# STM32MP25_CM33 register map
File version: 1.3
CPU: CM33 r0p1, little endian, MPU, FPU, vendor SysTick, 8 interrupt priority bits
Registers are 32-bit, read-write, reset 0x0 unless marked. A register's access mark holds for its fields unless they carry their own. Offsets are from the block's base; [hi:lo] are bit positions; lines under a group give offsets from that group; {n}, {i} and the like mark numbered series; 'fields as' and 'values as' point back to an identical list.

## RCC (part 2 of 3) — RCC register block
Base 0x44200000
Same registers: RCC_S 0x54200000
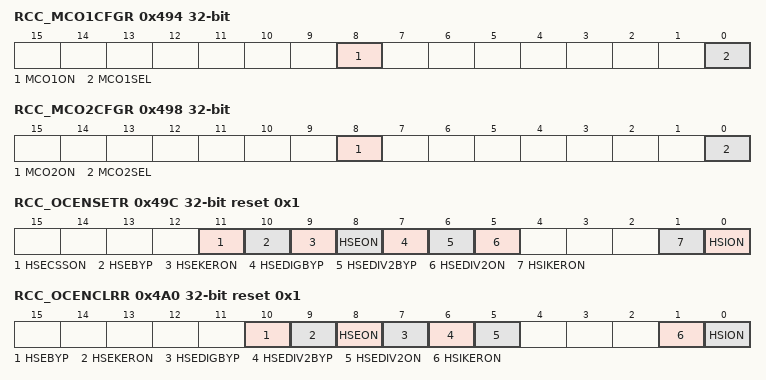
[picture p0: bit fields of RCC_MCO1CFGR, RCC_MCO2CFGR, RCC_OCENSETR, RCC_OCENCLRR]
0x494 RCC_MCO1CFGR — RCC MCO1 configuration register
  [8] MCO1ON — Control of MCO1 output
    0=MCO1 output disabled (default after reset); 1=MCO1 output enabled
  [0] MCO1SEL — MCO1 clock output selection
    0=Channel 61 output of the flexclkgen engine (default after reset); 1=Clock observation 0 of the flexclkgen engine
0x498 RCC_MCO2CFGR — RCC MCO2 configuration register
  [8] MCO2ON — Control of the MCO2 output
    0=MCO2 output disabled (default after reset); 1=MCO2 output enabled
  [0] MCO2SEL — MCO2 clock output selection
    0=Channel 62 output of the flexclkgen engine (default after reset); 1=Clock observation 1 of the flexclkgen engine
0x49C RCC_OCENSETR reset 0x1 — RCC oscillator clock enable set register
  [11] HSECSSON — HSECSSON bit set
    0=Reading 0 means that CSS on HSE is off (default after reset); 1=Writing 1 enables CSS on HSE
  [10] HSEBYP — HSEBYP bit set
    0=No effect; 1=Set the HSEBYP bit
  [9] HSEKERON — HSEKERON bit set
    0=No effect; 1=Set the HSEKERON bit
  [8] HSEON — HSEON bit set
    0=No effect; 1=Set HSEON bit
  [7] HSEDIGBYP — HSEDIGBYP bit set
    0=No effect; 1=Set HSEDIGBYP bit (digital bypass)
  [6] HSEDIV2BYP — HSEDIV2BYP bit set
    0=No effect; 1=Set HSEDIV2BYP bit
  [5] HSEDIV2ON — HSEDIV2ON bit set
    0=No effect; 1=Set HSEDIV2ON bit
  [1] HSIKERON — HSIKERON bit set
    0=No effect; 1=Set the HSIKERON bit
  [0] HSION — HSION bit set
    0=No effect; 1=Set the HSION bit
0x4A0 RCC_OCENCLRR reset 0x1 — RCC oscillator clock enable clear register
  [10] HSEBYP — HSEBYP bit clear
    0=No effect; 1=Clear the HSEBYP bit
  [9] HSEKERON — HSEKERON bit clear
    0=No effect; 1=Clear the HSEKERON bit
  [8] HSEON — HSEON bit clear
    0=No effect; 1=Clear the HSEON bit
  [7] HSEDIGBYP — HSEDIGBYP bit clear
    0=No effect; 1=Clear the HSEDIGBYP bit (analog bypass)
  [6] HSEDIV2BYP — HSEDIV2BYP bit clear
    0=No effect; 1=Clear the HSEDIV2BYP bit
  [5] HSEDIV2ON — HSEDIV2ON bit clear
    0=No effect; 1=Clear HSEDIV2ON bit
  [1] HSIKERON — HSIKERON bit clear
    0=No effect; 1=Clear the HSIKERON bit
  [0] HSION — HSION bit clear
    0=No effect; 1=Clear the HSION bit
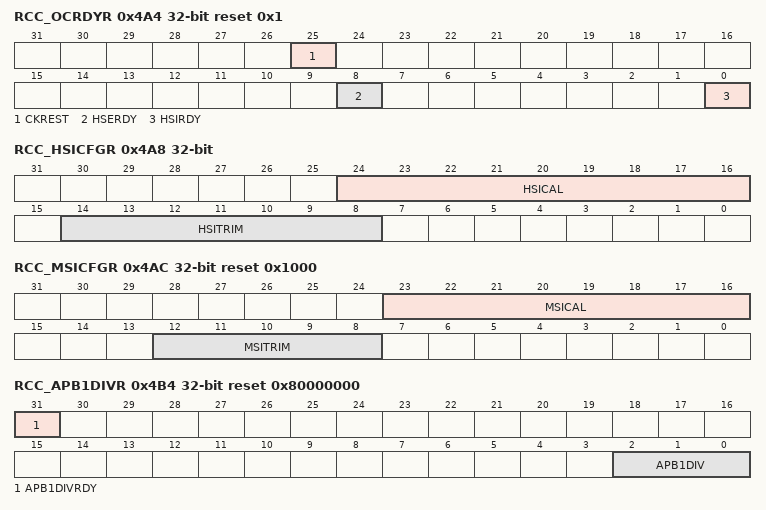
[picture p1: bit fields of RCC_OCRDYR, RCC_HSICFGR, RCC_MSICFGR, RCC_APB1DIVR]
0x4A4 RCC_OCRDYR ro reset 0x1 — RCC oscillator clock ready register
  [25] CKREST — Clock restore state machine status
    0=Clock restore process not ongoing (default after reset); 1=Clock restore process ongoing
  [8] HSERDY — HSE clock ready flag
    0=HSE clock not ready (default after reset); 1=HSE clock ready
  [0] HSIRDY — HSI clock ready flag
    0=HSI clock not ready (default after reset); 1=HSI clock ready
0x4A8 RCC_HSICFGR — RCC HSI configuration register
  [24:16] HSICAL ro — HSI clock calibration
  [14:8] HSITRIM — HSI clock trimming
    64=bsec_hsi_cal[8:0] - 64; 65=bsec_hsi_cal[8:0] - 63; 0=bsec_hsi_cal[8:0] (default after reset); 62=bsec_hsi_cal[8:0] + 62; 63=bsec_hsi_cal[8:0] + 63
0x4AC RCC_MSICFGR reset 0x1000 — RCC MSI configuration register
  [23:16] MSICAL ro — MSI clock calibration
  [12:8] MSITRIM — MSI clock trimming
0x4B0 RCC_RTCDIVR — RCC RTC clock divider register
  [5:0] RTCDIV — HSE division factor for RTC clock
    0=HSE (default after reset); 1=HSE/2; 2=HSE/3; 3=HSE/4; 62=HSE/63; 63=HSE/64
0x4B4 RCC_APB1DIVR reset 0x80000000 — RCC APB1 clock divider register
  [31] APB1DIVRDY ro — APB1 clock prescaler status
    0=The new division factor is not yet taken into account; 1=The new division factor is taken into account (default after reset)
  [2:0] APB1DIV — APB1 clock divider
    0=ck_icn_ls_mcu (default after reset); 1=ck_icn_ls_mcu / 2; 2=ck_icn_ls_mcu / 4; 3=ck_icn_ls_mcu / 8; 4=ck_icn_ls_mcu / 16
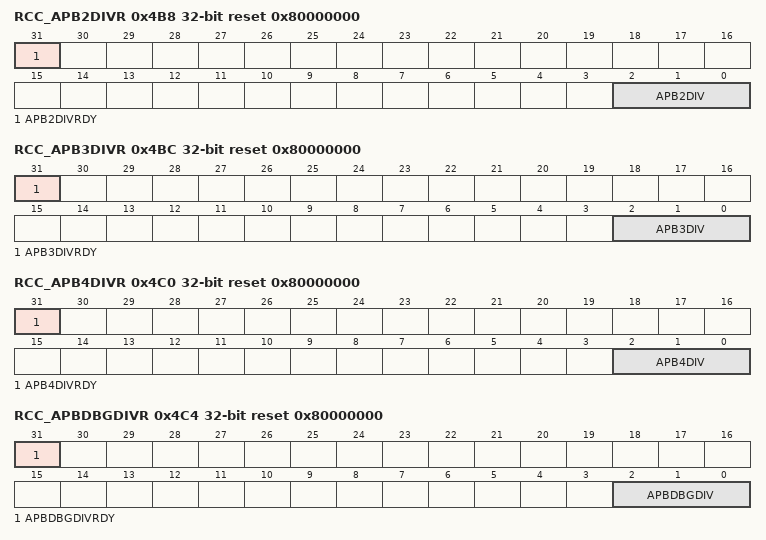
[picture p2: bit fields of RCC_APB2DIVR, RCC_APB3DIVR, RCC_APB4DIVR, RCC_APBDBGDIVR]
0x4B8 RCC_APB2DIVR reset 0x80000000 — RCC APB2 clock divider register
  [31] APB2DIVRDY ro — APB2 clock prescaler status
    values as RCC_APB1DIVR.APB1DIVRDY
  [2:0] APB2DIV — APB2 clock divider
    values as RCC_APB1DIVR.APB1DIV
0x4BC RCC_APB3DIVR reset 0x80000000 — RCC APB3 clock divider register
  [31] APB3DIVRDY ro — APB3 clock prescaler status
    0=The new division factor is not yet taken into account; 1=The new division factor is taken into account
  [2:0] APB3DIV — APB3 clock divider
    values as RCC_APB1DIVR.APB1DIV
0x4C0 RCC_APB4DIVR reset 0x80000000 — RCC APB4 clock divider register
  [31] APB4DIVRDY ro — APB4 clock divider status
    values as RCC_APB1DIVR.APB1DIVRDY
  [2:0] APB4DIV — APB4 clock divider
    values as RCC_APB1DIVR.APB1DIV
0x4C4 RCC_APBDBGDIVR reset 0x80000000 — RCC APBDBG clock divider register
  [31] APBDBGDIVRDY ro — APBDBG clock divider status
    values as RCC_APB1DIVR.APB1DIVRDY
  [2:0] APBDBGDIV — APBDBG clock divider
    values as RCC_APB1DIVR.APB1DIV
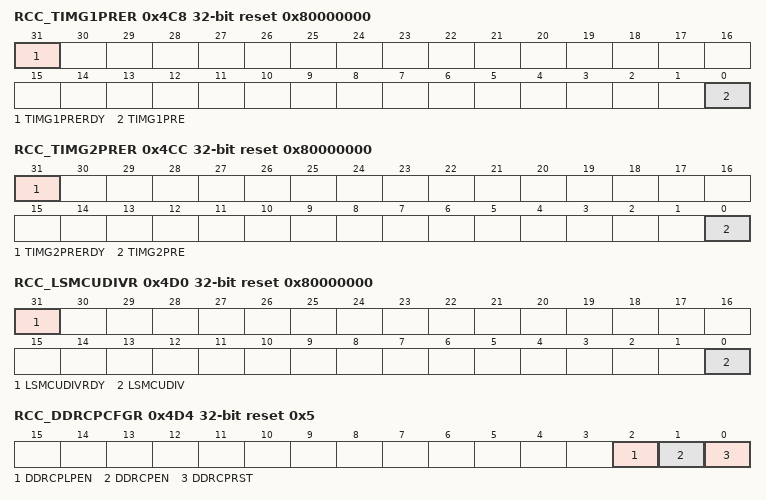
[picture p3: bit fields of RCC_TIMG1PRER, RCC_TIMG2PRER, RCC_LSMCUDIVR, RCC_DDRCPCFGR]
0x4C8 RCC_TIMG1PRER reset 0x80000000 — RCC TIM group 1 prescaler register
  [31] TIMG1PRERDY ro — Clock prescaler status for timers of group 1
    values as RCC_APB1DIVR.APB1DIVRDY
  [0] TIMG1PRE — Clock prescaler selection for timers of group 1
    0=Timer kernel clock is equal to ck_icn_ls_mcu if APB1DIV corresponds to a division; 1=Timer kernel clock is equal to ck_icn_ls_mcu if APB1DIV corresponds to a division
0x4CC RCC_TIMG2PRER reset 0x80000000 — RCC TIM group 2 prescaler register
  [31] TIMG2PRERDY ro — Clock prescaler status for timers of group 2
    values as RCC_APB3DIVR.APB3DIVRDY
  [0] TIMG2PRE — Clock prescaler selection for timers of group 2
    0=Timer kernel clock is equal to ck_icn_ls_mcu if APB2DIV corresponds to a division; 1=Timer kernel clock is equal to ck_icn_ls_mcu if APB2DIV corresponds to division
0x4D0 RCC_LSMCUDIVR reset 0x80000000 — RCC LSMCU clock divider register
  [31] LSMCUDIVRDY ro — LSMCU clock divider status
    values as RCC_APB1DIVR.APB1DIVRDY
  [0] LSMCUDIV — LSMCU clock divider
    0=ck_icn_hs_mcu (default after reset); 1=ck_icn_hs_mcu / 2
0x4D4 RCC_DDRCPCFGR reset 0x5 — RCC DDRC AXI port configuration register
  [2] DDRCPLPEN — DDRC AXI port clock enable during CSleep
    0=Writing 0 disables peripheral clocks in CSleep; 1=Writing 1 enables peripheral clocks in CSleep
  [1] DDRCPEN — DDRC AXI port clock enable
    0=Writing 0 disables peripheral clocks; 1=Writing 1 enables peripheral clocks
  [0] DDRCPRST — DDRC AXI port reset
    0=Writing 0 releases DDRC AXI port interface reset; 1=Writing 1 sets DDRC AXI port interface under reset
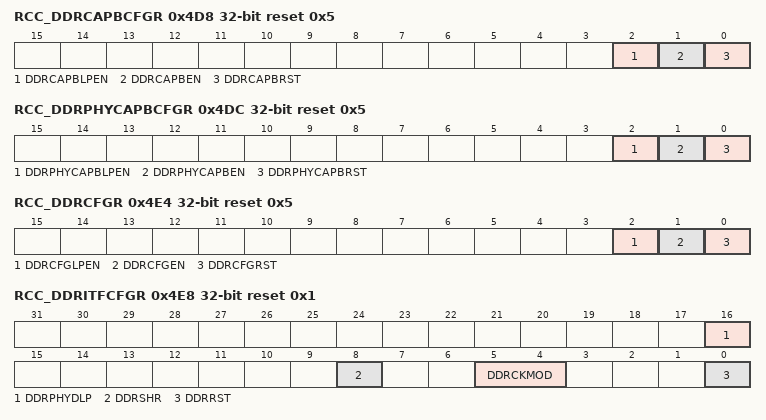
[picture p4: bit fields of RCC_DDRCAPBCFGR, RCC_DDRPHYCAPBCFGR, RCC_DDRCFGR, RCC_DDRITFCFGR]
0x4D8 RCC_DDRCAPBCFGR reset 0x5 — RCC DDRC APB configuration register
  [2] DDRCAPBLPEN — DDRC APB clock enable during CSleep
    values as RCC_DDRCPCFGR.DDRCPLPEN
  [1] DDRCAPBEN — DDRC APB clock enable
    values as RCC_DDRCPCFGR.DDRCPEN
  [0] DDRCAPBRST — DDRC APB reset
    0=Writing 0 releases DDRC APB interface reset; 1=Writing 1 sets DDRC APB interface under reset
0x4DC RCC_DDRPHYCAPBCFGR reset 0x5 — RCC DDRPHYC APB configuration register
  [2] DDRPHYCAPBLPEN — DDRPHYC APB clock enable during CSleep
    values as RCC_DDRCPCFGR.DDRCPLPEN
  [1] DDRPHYCAPBEN — DDRPHYC APB clock enable
    values as RCC_DDRCPCFGR.DDRCPEN
  [0] DDRPHYCAPBRST — DDRPHYC APB reset
    0=Writing 0 releases DDRPHYC APB interface reset; 1=Writing 1 sets DDRPHYC APB interface under reset
0x4E0 RCC_DDRPHYCCFGR — RCC DDRPHYC configuration register
  [1] DDRPHYCEN — DDRPHYC kernel clock enable
    0=Writing 0 disables DDRPHYC kernel clock; 1=Writing 1 enables DDRPHYC kernel clock
0x4E4 RCC_DDRCFGR reset 0x5 — RCC DDR configuration register
  [2] DDRCFGLPEN — DDR APB configuration clock enable during CSleep
    values as RCC_DDRCPCFGR.DDRCPLPEN
  [1] DDRCFGEN — DDR APB configuration clock enable
    values as RCC_DDRCPCFGR.DDRCPEN
  [0] DDRCFGRST — DDR APB configuration reset
    0=Writing 0 releases DDR APB configuration interface reset; 1=Writing 1 sets DDR APB configuration interface under reset
0x4E8 RCC_DDRITFCFGR reset 0x1 — RCC DDR interface configuration register
  [16] DDRPHYDLP — DDRPHY deep low-power mode (LP2 or LP3)
    0=DDRPHY not set in low-power mode (default after reset); 1=DDRPHY set in deep low-power mode
  [8] DDRSHR — DDR peripheral mode
    0=DDR defined as single peripheral (default after reset); 1=DDR defined as shared peripheral
  [5:4] DDRCKMOD — RCC mode for DDR clock control
    0=Normal mode: dphy_ker_ck and dphy_ker_byp_ck gating depends on DDRPHYCEN, DDRSHR, DDRPHYDLP, and CPU1 or system mode; 1=ASR (automatic self-refresh) mode: ddrc_ker_ck is gated automatically according to cactive_ddrc signal; 2=HSR (hardware self-refresh) mode: ddrc_ker_ck gating depends on DDRCPEN, DDRCLPEN, DDRSHR, and CPU1 or system mode
  [0] DDRRST — DDR core and PHY reset
    0=DDR core and PHY are not reset; 1=DDR core and PHY are reset (default after reset)
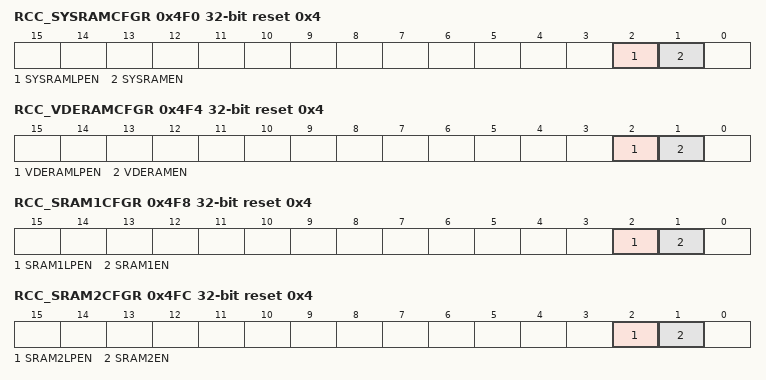
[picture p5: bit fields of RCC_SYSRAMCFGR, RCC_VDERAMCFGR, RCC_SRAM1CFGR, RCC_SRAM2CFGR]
0x4F0 RCC_SYSRAMCFGR reset 0x4 — RCC SYSRAM configuration register
  [2] SYSRAMLPEN — SYSRAM clock enable during CSleep
    values as RCC_DDRCPCFGR.DDRCPLPEN
  [1] SYSRAMEN — SYSRAM clock enable
    values as RCC_DDRCPCFGR.DDRCPEN
0x4F4 RCC_VDERAMCFGR reset 0x4 — RCC VDERAM configuration register
  [2] VDERAMLPEN — VDERAM clock enable during CSleep
    values as RCC_DDRCPCFGR.DDRCPLPEN
  [1] VDERAMEN — VDERAM clock enable
    values as RCC_DDRCPCFGR.DDRCPEN
0x4F8 RCC_SRAM1CFGR reset 0x4 — RCC SRAM1 configuration register
  [2] SRAM1LPEN — SRAM1 clock enable during CSleep
    values as RCC_DDRCPCFGR.DDRCPLPEN
  [1] SRAM1EN — SRAM1 clock enable
    values as RCC_DDRCPCFGR.DDRCPEN
0x4FC RCC_SRAM2CFGR reset 0x4 — RCC SRAM2 configuration register
  [2] SRAM2LPEN — SRAM2 clock enable during CSleep
    values as RCC_DDRCPCFGR.DDRCPLPEN
  [1] SRAM2EN — SRAM2 clock enable
    values as RCC_DDRCPCFGR.DDRCPEN
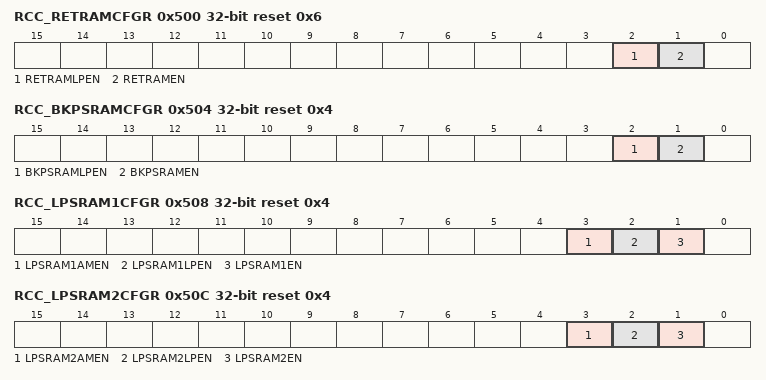
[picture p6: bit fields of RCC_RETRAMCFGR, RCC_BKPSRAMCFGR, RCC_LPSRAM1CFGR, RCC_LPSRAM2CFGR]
0x500 RCC_RETRAMCFGR reset 0x6 — RCC RETRAM configuration register
  [2] RETRAMLPEN — RETRAM clock enable during CSleep
    values as RCC_DDRCPCFGR.DDRCPLPEN
  [1] RETRAMEN — RETRAM clock enable
    values as RCC_DDRCPCFGR.DDRCPEN
0x504 RCC_BKPSRAMCFGR reset 0x4 — RCC BKPSRAM configuration register
  [2] BKPSRAMLPEN — BKPSRAM clock enable during CSleep
    values as RCC_DDRCPCFGR.DDRCPLPEN
  [1] BKPSRAMEN — BKPSRAM clock enable
    values as RCC_DDRCPCFGR.DDRCPEN
0x508 RCC_LPSRAM1CFGR reset 0x4 — RCC LPSRAM1 configuration register
  [3] LPSRAM1AMEN — LPSRAM1 autonomous clock mode enable
    0=Writing 0 disables autonomous clock mode; 1=Writing 1 enables autonomous clock mode
  [2] LPSRAM1LPEN — LPSRAM1 clock enable during CSleep
    values as RCC_DDRCPCFGR.DDRCPLPEN
  [1] LPSRAM1EN — LPSRAM1 clock enable
    values as RCC_DDRCPCFGR.DDRCPEN
0x50C RCC_LPSRAM2CFGR reset 0x4 — RCC LPSRAM2 configuration register
  [3] LPSRAM2AMEN — LPSRAM2 autonomous clock mode enable
    0=Writing 0 disables autonomous clock mode; 1=Writing 1 enables the autonomous clock mode
  [2] LPSRAM2LPEN — LPSRAM2 clock enable during CSleep
    values as RCC_DDRCPCFGR.DDRCPLPEN
  [1] LPSRAM2EN — LPSRAM2 clock enable
    values as RCC_DDRCPCFGR.DDRCPEN
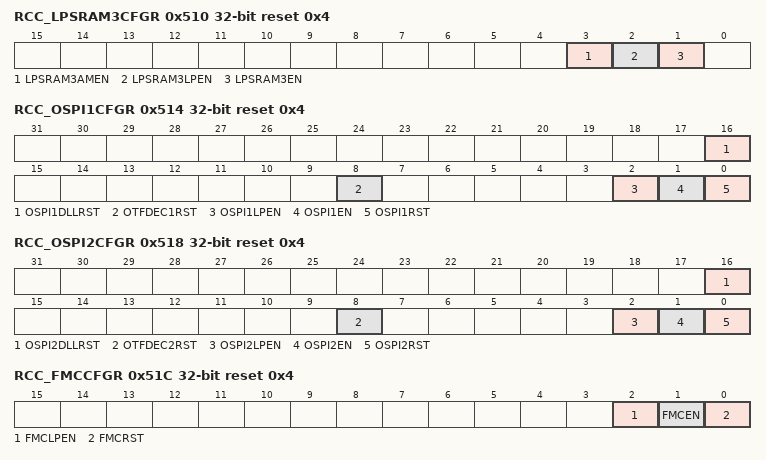
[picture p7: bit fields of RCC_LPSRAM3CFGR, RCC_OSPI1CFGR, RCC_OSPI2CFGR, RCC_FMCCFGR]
0x510 RCC_LPSRAM3CFGR reset 0x4 — RCC LPSRAM3 configuration register
  [3] LPSRAM3AMEN — LPSRAM3 autonomous clock mode enable
    values as RCC_LPSRAM2CFGR.LPSRAM2AMEN
  [2] LPSRAM3LPEN — LPSRAM3 clock enable during CSleep
    values as RCC_DDRCPCFGR.DDRCPLPEN
  [1] LPSRAM3EN — LPSRAM3 clock enable
    values as RCC_DDRCPCFGR.DDRCPEN
0x514 RCC_OSPI1CFGR reset 0x4 — RCC OCTOSPI1 configuration register
  [16] OSPI1DLLRST — OCTOSPI1 DLL reset
    0=Writing 0 releases OCTOSPI1 DLL reset; 1=Writing 1 asserts OCTOSPI1 DLL reset
  [8] OTFDEC1RST — OTFDEC1 reset
    0=Writing 0 releases OTFDEC1 reset; 1=Writing 1 asserts OTFDEC1 reset
  [2] OSPI1LPEN — OCTOSPI1, OTFDEC1 and OCTOSPI1 delay (DLYBOSPI1) clock enable duringCSleep
    values as RCC_DDRCPCFGR.DDRCPLPEN
  [1] OSPI1EN — OCTOSPI1 and OTFDEC1 clock enable
    values as RCC_DDRCPCFGR.DDRCPEN
  [0] OSPI1RST — OCTOSPI1 reset
    0=Writing 0 releases OCTOSPI1 reset; 1=Writing 1 asserts OCTOSPI1 reset
0x518 RCC_OSPI2CFGR reset 0x4 — RCC OCTOSPI2 configuration register
  [16] OSPI2DLLRST — OCTOSPI2 DLL reset
    0=Writing 0 releases OCTOSPI2 DLL reset; 1=Writing 1 asserts OCTOSPI2 DLL reset
  [8] OTFDEC2RST — OTFDEC2 reset
    0=Writing 0 releases OTFDEC2 reset; 1=Writing 1 asserts OTFDEC2 reset
  [2] OSPI2LPEN — OCTOSPI2 and OTFDEC2 clock enable during CSleep
    values as RCC_DDRCPCFGR.DDRCPLPEN
  [1] OSPI2EN — OCTOSPI2 and OTFDEC2 clock enable
    values as RCC_DDRCPCFGR.DDRCPEN
  [0] OSPI2RST — OCTOSPI2 reset
    0=Writing 0 releases OCTOSPI2 reset; 1=Writing 1 asserts OCTOSPI2 reset
0x51C RCC_FMCCFGR reset 0x4 — RCC FMC configuration register
  [2] FMCLPEN — FMC clock enable during CSleep
    values as RCC_DDRCPCFGR.DDRCPLPEN
  [1] FMCEN — FMC clock enable
    values as RCC_DDRCPCFGR.DDRCPEN
  [0] FMCRST — FMC reset
    0=Writing 0 releases FMC reset; 1=Writing 1 asserts FMC reset
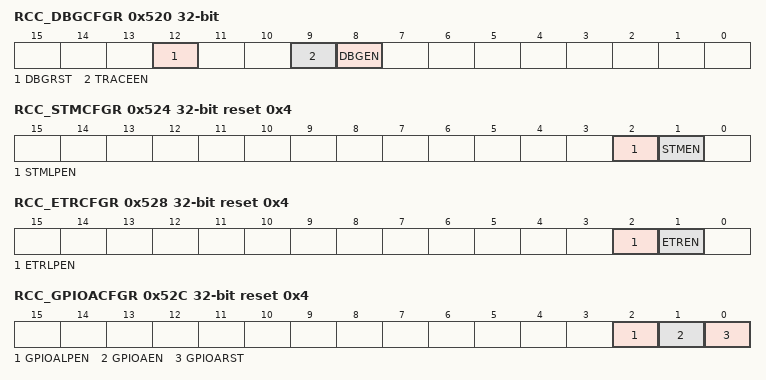
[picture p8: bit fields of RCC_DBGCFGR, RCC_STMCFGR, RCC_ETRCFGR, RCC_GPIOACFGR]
0x520 RCC_DBGCFGR — RCC debug configuration register
  [12] DBGRST — Debug function reset
    0=Trace and debug parts are not reset (default after reset); 1=Trace and debug parts are under reset
  [9] TRACEEN — Clock enable for trace port interface
    0=Clock for trace function disabled (default after reset); 1=Clock for trace function enabled
  [8] DBGEN — Debug function clock enable
    0=Enabling of clocks for debug function is controlled by cdbgpwrupreq signal from DAP (default after reset); 1=Clocks for debug function are enabled
0x524 RCC_STMCFGR reset 0x4 — RCC STM configuration register
  [2] STMLPEN — STM clock enable during CSleep
    values as RCC_DDRCPCFGR.DDRCPLPEN
  [1] STMEN — STM clock enable
    values as RCC_DDRCPCFGR.DDRCPEN
0x528 RCC_ETRCFGR reset 0x4 — RCC ETR configuration register
  [2] ETRLPEN — ETR clock enable during CSleep
    values as RCC_DDRCPCFGR.DDRCPLPEN
  [1] ETREN — ETR clocks enable
    values as RCC_DDRCPCFGR.DDRCPEN
0x52C RCC_GPIOACFGR reset 0x4 — RCC GPIOA configuration register
  [2] GPIOALPEN — GPIO x clock enable during CSleep
    values as RCC_DDRCPCFGR.DDRCPLPEN
  [1] GPIOAEN — GPIO x clock enable
    values as RCC_DDRCPCFGR.DDRCPEN
  [0] GPIOARST — GPIO x reset
    0=Writing 0 releases GPIOx reset; 1=Writing 1 asserts GPIOx reset
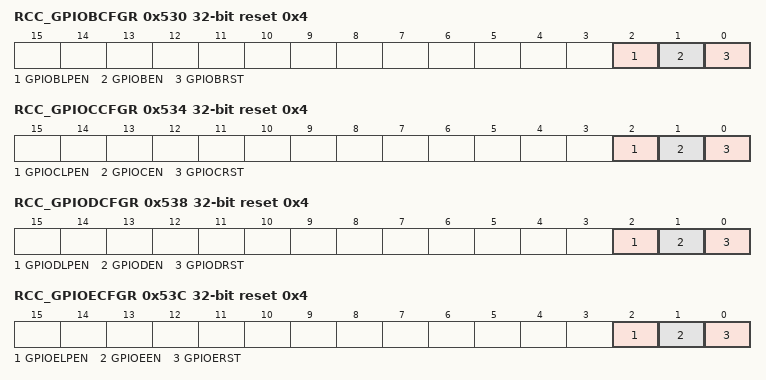
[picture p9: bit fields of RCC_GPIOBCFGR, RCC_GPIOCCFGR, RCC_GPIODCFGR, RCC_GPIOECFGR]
0x530 RCC_GPIOBCFGR reset 0x4 — RCC GPIOB configuration register
  [2] GPIOBLPEN — GPIO x clock enable during CSleep
    values as RCC_DDRCPCFGR.DDRCPLPEN
  [1] GPIOBEN — GPIO x clock enable
    values as RCC_DDRCPCFGR.DDRCPEN
  [0] GPIOBRST — GPIO x reset
    values as RCC_GPIOACFGR.GPIOARST
0x534 RCC_GPIOCCFGR reset 0x4 — RCC GPIOC configuration register
  [2] GPIOCLPEN — GPIO x clock enable during CSleep
    values as RCC_DDRCPCFGR.DDRCPLPEN
  [1] GPIOCEN — GPIO x clock enable
    values as RCC_DDRCPCFGR.DDRCPEN
  [0] GPIOCRST — GPIO x reset
    values as RCC_GPIOACFGR.GPIOARST
0x538 RCC_GPIODCFGR reset 0x4 — RCC GPIOD configuration register
  [2] GPIODLPEN — GPIO x clock enable during CSleep
    values as RCC_DDRCPCFGR.DDRCPLPEN
  [1] GPIODEN — GPIO x clock enable
    values as RCC_DDRCPCFGR.DDRCPEN
  [0] GPIODRST — GPIO x reset
    values as RCC_GPIOACFGR.GPIOARST
0x53C RCC_GPIOECFGR reset 0x4 — RCC GPIOE configuration register
  [2] GPIOELPEN — GPIO x clock enable during CSleep
    values as RCC_DDRCPCFGR.DDRCPLPEN
  [1] GPIOEEN — GPIO x clock enable
    values as RCC_DDRCPCFGR.DDRCPEN
  [0] GPIOERST — GPIO x reset
    values as RCC_GPIOACFGR.GPIOARST
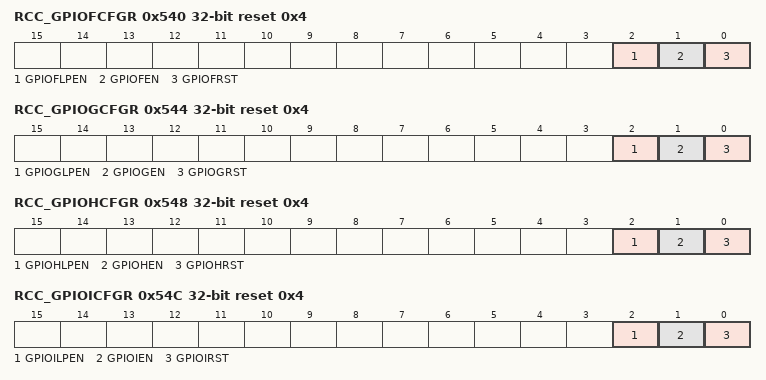
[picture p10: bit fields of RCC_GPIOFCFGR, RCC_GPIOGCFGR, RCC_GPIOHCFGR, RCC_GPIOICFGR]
0x540 RCC_GPIOFCFGR reset 0x4 — RCC GPIOF configuration register
  [2] GPIOFLPEN — GPIO x clock enable during CSleep
    values as RCC_DDRCPCFGR.DDRCPLPEN
  [1] GPIOFEN — GPIO x clock enable
    values as RCC_DDRCPCFGR.DDRCPEN
  [0] GPIOFRST — GPIO x reset
    values as RCC_GPIOACFGR.GPIOARST
0x544 RCC_GPIOGCFGR reset 0x4 — RCC GPIOG configuration register
  [2] GPIOGLPEN — GPIO x clock enable during CSleep
    values as RCC_DDRCPCFGR.DDRCPLPEN
  [1] GPIOGEN — GPIO x clock enable
    values as RCC_DDRCPCFGR.DDRCPEN
  [0] GPIOGRST — GPIO x reset
    values as RCC_GPIOACFGR.GPIOARST
0x548 RCC_GPIOHCFGR reset 0x4 — RCC GPIOH configuration register
  [2] GPIOHLPEN — GPIO x clock enable during CSleep
    values as RCC_DDRCPCFGR.DDRCPLPEN
  [1] GPIOHEN — GPIO x clock enable
    values as RCC_DDRCPCFGR.DDRCPEN
  [0] GPIOHRST — GPIO x reset
    values as RCC_GPIOACFGR.GPIOARST
0x54C RCC_GPIOICFGR reset 0x4 — RCC GPIOI configuration register
  [2] GPIOILPEN — GPIO x clock enable during CSleep
    values as RCC_DDRCPCFGR.DDRCPLPEN
  [1] GPIOIEN — GPIO x clock enable
    values as RCC_DDRCPCFGR.DDRCPEN
  [0] GPIOIRST — GPIO x reset
    values as RCC_GPIOACFGR.GPIOARST
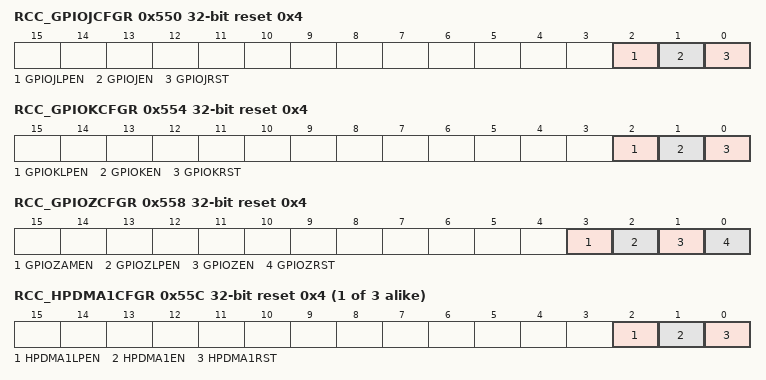
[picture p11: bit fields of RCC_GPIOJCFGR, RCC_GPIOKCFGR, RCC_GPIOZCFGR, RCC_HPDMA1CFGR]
0x550 RCC_GPIOJCFGR reset 0x4 — RCC GPIOJ configuration register
  [2] GPIOJLPEN — GPIO x clock enable during CSleep
    values as RCC_DDRCPCFGR.DDRCPLPEN
  [1] GPIOJEN — GPIO x clock enable
    values as RCC_DDRCPCFGR.DDRCPEN
  [0] GPIOJRST — GPIO x reset
    values as RCC_GPIOACFGR.GPIOARST
0x554 RCC_GPIOKCFGR reset 0x4 — RCC GPIOK configuration register
  [2] GPIOKLPEN — GPIO x clock enable during CSleep
    values as RCC_DDRCPCFGR.DDRCPLPEN
  [1] GPIOKEN — GPIO x clock enable
    values as RCC_DDRCPCFGR.DDRCPEN
  [0] GPIOKRST — GPIO x reset
    values as RCC_GPIOACFGR.GPIOARST
0x558 RCC_GPIOZCFGR reset 0x4 — RCC GPIOZ configuration register
  [3] GPIOZAMEN — GPIOZ autonomous clock mode enable
    0=Writing 0 disables the autonomous clock mode; 1=Writing 1 enables the autonomous clock mode
  [2] GPIOZLPEN — GPIOZ clock enable during CSleep
    values as RCC_DDRCPCFGR.DDRCPLPEN
  [1] GPIOZEN — GPIOZ clock enable
    values as RCC_DDRCPCFGR.DDRCPEN
  [0] GPIOZRST — GPIOZ reset
    0=Writing 0 releases GPIOZ reset; 1=Writing 1 asserts GPIOZ reset
{0x558+4i} RCC_HPDMA{i}CFGR reset 0x4 (i=1..3) — RCC HPDMA{i} configuration register
  [2] HPDMA{i}LPEN — HPDMA{i} clock enable during CSleep
    values as RCC_DDRCPCFGR.DDRCPLPEN
  [1] HPDMA{i}EN — HPDMA{i} clock enable
    values as RCC_DDRCPCFGR.DDRCPEN
  [0] HPDMA{i}RST — HPDMA{i} reset
    0=Writing 0 releases HPDMA{i} reset; 1=Writing 1 asserts HPDMA{i} reset
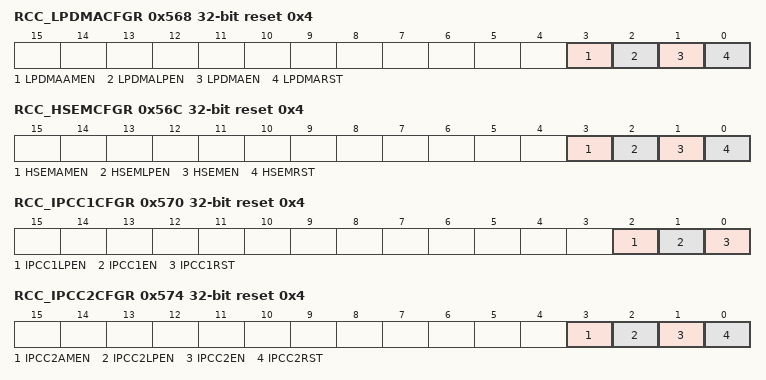
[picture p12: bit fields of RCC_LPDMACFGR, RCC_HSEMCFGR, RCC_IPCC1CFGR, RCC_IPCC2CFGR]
0x568 RCC_LPDMACFGR reset 0x4 — RCC LPDMA1 configuration register
  [3] LPDMAAMEN — LPDMA1 autonomous clock mode enable
    values as RCC_LPSRAM1CFGR.LPSRAM1AMEN
  [2] LPDMALPEN — LPDMA1 clock enable during CSleep
    values as RCC_DDRCPCFGR.DDRCPLPEN
  [1] LPDMAEN — LPDMA1 clock enable
    values as RCC_DDRCPCFGR.DDRCPEN
  [0] LPDMARST — LPDMA1 reset
    0=Writing 0 releases LPDMA1 reset; 1=Writing 1 asserts LPDMA1 reset
0x56C RCC_HSEMCFGR reset 0x4 — RCC HSEM configuration register
  [3] HSEMAMEN — HSEM autonomous clock mode enable
    values as RCC_LPSRAM1CFGR.LPSRAM1AMEN
  [2] HSEMLPEN — HSEM clock enable during CSleep
    values as RCC_DDRCPCFGR.DDRCPLPEN
  [1] HSEMEN — HSEM clock enable
    values as RCC_DDRCPCFGR.DDRCPEN
  [0] HSEMRST — HSEM reset
    0=Writing 0 releases HSEM reset; 1=Writing 1 asserts HSEM reset
0x570 RCC_IPCC1CFGR reset 0x4 — RCC IPCC1 configuration register
  [2] IPCC1LPEN — IPCC1 clock enable during CSleep
    values as RCC_DDRCPCFGR.DDRCPLPEN
  [1] IPCC1EN — IPCC1 clock enable
    values as RCC_DDRCPCFGR.DDRCPEN
  [0] IPCC1RST — IPCC1 reset
    0=Writing 0 releases IPCC1 reset; 1=Writing 1 asserts IPCC1 reset
0x574 RCC_IPCC2CFGR reset 0x4 — RCC IPCC2 configuration register
  [3] IPCC2AMEN — IPCC2 autonomous clock mode enable
    values as RCC_LPSRAM1CFGR.LPSRAM1AMEN
  [2] IPCC2LPEN — IPCC2 clock enable during CSleep
    values as RCC_DDRCPCFGR.DDRCPLPEN
  [1] IPCC2EN — IPCC2 clock enable
    values as RCC_DDRCPCFGR.DDRCPEN
  [0] IPCC2RST — IPCC2 reset
    0=Writing 0 releases IPCC2 reset; 1=Writing 1 asserts IPCC2 reset
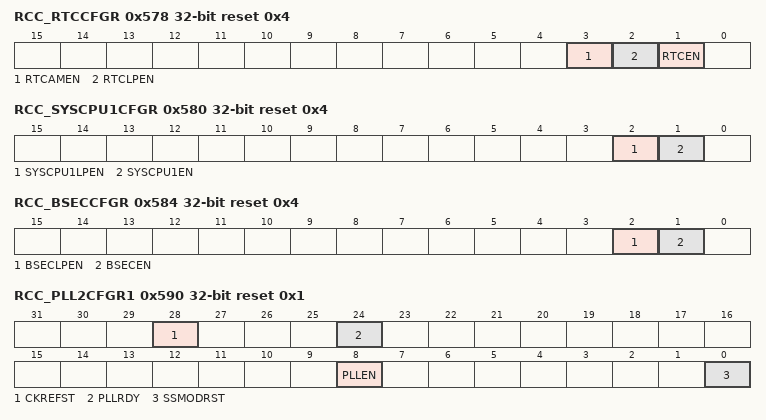
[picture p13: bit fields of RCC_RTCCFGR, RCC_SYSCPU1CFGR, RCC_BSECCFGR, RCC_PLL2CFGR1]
0x578 RCC_RTCCFGR reset 0x4 — RCC RTC configuration register
  [3] RTCAMEN — RTC autonomous clock mode enable
    values as RCC_LPSRAM1CFGR.LPSRAM1AMEN
  [2] RTCLPEN — RTC bus clock enable during CSleep
    0=Writing 0 disables APB clock in CSleep; 1=Writing 1 enables APB clock in CSleep
  [1] RTCEN — RTC bus clock enable
    0=Writing 0 disables APB clock; 1=Writing 1 enables APB clock
0x580 RCC_SYSCPU1CFGR reset 0x4 — RCC SYSCPU1 configuration register
  [2] SYSCPU1LPEN — CPU1 system configuration clock enable during CSleep
    values as RCC_RTCCFGR.RTCLPEN
  [1] SYSCPU1EN — CPU1 system configuration clock enable
    values as RCC_RTCCFGR.RTCEN
0x584 RCC_BSECCFGR reset 0x4 — RCC BSEC configuration register
  [2] BSECLPEN — BSEC clock enable during CSleep
    values as RCC_RTCCFGR.RTCLPEN
  [1] BSECEN — BSEC clock enable
    values as RCC_RTCCFGR.RTCEN
0x590 RCC_PLL2CFGR1 reset 0x1 — RCC PLL2 configuration register 1
  [28] CKREFST — PLLx reference clock state
    0=Reading 0 means that PLLx reference clock is not running; 1=Reading 1 means that PLLx reference clock is running
  [24] PLLRDY ro — PLLx clock ready flag
    0=PLLx unlocked (default after reset); 1=PLLx locked
  [8] PLLEN — PLLx enable
    0=PLLx off (default after reset); 1=PLLx on
  [0] SSMODRST — PLLx spread-spectrum modulator reset
    0=PLLx spread-spectrum modulator reset module is released; 1=PLLx spread-spectrum modulator reset module is asserted (default after reset)
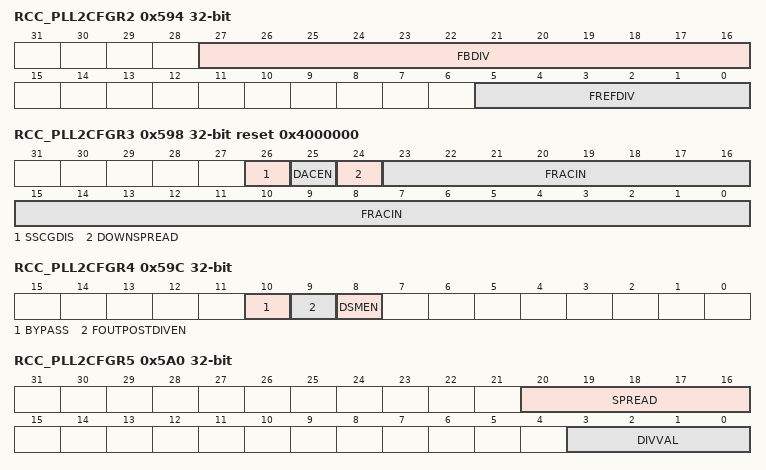
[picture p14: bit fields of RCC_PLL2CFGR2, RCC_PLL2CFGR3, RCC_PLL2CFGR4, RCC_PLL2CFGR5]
0x594 RCC_PLL2CFGR2 — RCC PLL2 configuration register 2
  [27:16] FBDIV — PLLx VCO multiplication factor
  [5:0] FREFDIV — PLLx reference input clock divide frequency ratio
    0=Not applicable when PLLx is enabled; 1=FREF divided by 1 (min value); 2=FREF divided by 2; 3=FREF divided by 3; {v}=FREF divided by {v} (v=60..63)
0x598 RCC_PLL2CFGR3 reset 0x4000000 — RCC PLL2 configuration register 3
  [26] SSCGDIS — PLLx spread-spectrum modulator enable
    0=PLLx spread-spectrum modulator enabled; 1=PLLx spread-spectrum modulator disabled (default after reset)
  [25] DACEN — PLLx noise canceling DAC enable in fractional mode
    0=DAC not active (default after reset); 1=DAC active
  [24] DOWNSPREAD — PLLx VCO frequency modulation mode
    0=Center-spread modulation selected (default after reset); 1=Down-spread modulation selected
  [23:0] FRACIN — Fractional part of PLLx VCO multiplication factor
0x59C RCC_PLL2CFGR4 — RCC PLL2 configuration register 4
  [10] BYPASS — PLLx FOUTPOSTDIV bypass
    0=FOUTPOSTDIV driven by POSTDIV2; 1=FOUTPOSTDIV driven by FREF
  [9] FOUTPOSTDIVEN — PLLx output and post divider enable
    0=FOUTPOSTDIV output, POSTDIV1, and POSTDIV2 are powered down; 1=FOUTPOSTDIV output, POSTDIV1, and POSTDIV2 dividers are active
  [8] DSMEN — PLLx delta-sigma modulator enable
    0=DSM is powered down; 1=DSM is active
0x5A0 RCC_PLL2CFGR5 — RCC PLL2 configuration register 5
  [20:16] SPREAD — Modulation depth adjustment for PLLx
  [3:0] DIVVAL — Modulation frequency adjustment for PLLx
0x5A8 RCC_PLL2CFGR6 — RCC PLL2 configuration register 6
  [2:0] POSTDIV1 — PLLx VCO frequency divide level 1
    0=Not applicable; 1=FOUTVCO divided by 1 (minimum value); 6=FOUTVCO divided by 6; 7=FOUTVCO divided by 7
0x5AC RCC_PLL2CFGR7 — RCC PLL2 configuration register 7
  [2:0] POSTDIV2 — PLLx VCO frequency divide level 2
    0=Not applicable; 1=FOUTVCO/POSTDIV1 divided by 1 (minimum value); 6=FOUTVCO/POSTDIV1 divided by 6; 7=FOUTVCO/POSTDIV1 divided by 7
0x5B8 RCC_PLL3CFGR1 reset 0x1 — RCC PLL3 configuration register 1
  fields as RCC_PLL2CFGR1
0x5BC RCC_PLL3CFGR2 — RCC PLL3 configuration register 2
  fields as RCC_PLL2CFGR2
0x5C0 RCC_PLL3CFGR3 reset 0x4000000 — RCC PLL3 configuration register 3
  fields as RCC_PLL2CFGR3
0x5C4 RCC_PLL3CFGR4 reset 0x600 — RCC PLL3 configuration register 4
  fields as RCC_PLL2CFGR4
0x5C8 RCC_PLL3CFGR5 — RCC PLL3 configuration register 5
  fields as RCC_PLL2CFGR5
0x5D0 RCC_PLL3CFGR6 — RCC PLL3 configuration register 6
  fields as RCC_PLL2CFGR6
0x5D4 RCC_PLL3CFGR7 — RCC PLL3 configuration register 7
  fields as RCC_PLL2CFGR7
0x5E0 RCC_HSIFMONCR reset 0x1F07A1 — RCC HSI frequency monitoring control register
  [31] HSIMONF — HSI clock period monitor interrupt flag
    0=No deviation detected on HSI clock period (default after reset); 1=Deviation detected on HSI clock period
  [30] HSIMONIE — HSI clock period monitor interrupt enable
    0=HSI clock period monitoring interrupt disabled (default after reset); 1=HSI clock period monitoring interrupt enabled
  [21:16] HSIDEV — HSI clock count deviation value
  [15] HSIMONEN — HSI clock period monitor enable
    0=Writing 0 disables HSI clock period monitoring; 1=Writing 1 enables HSI clock period monitoring
  [10:0] HSIREF — HSI clock count reference value
0x5E4 RCC_HSIFVALR ro — RCC HSI frequency value register
  [10:0] HSIVAL — HSI clock-cycle counter value
{0x6FC+4i} RCC_TIM{i}CFGR reset 0x4 (i=1..8) — RCC TIM{i} configuration register
  [2] TIM{i}LPEN — TIM{i} clock enable during CSleep
    values as RCC_DDRCPCFGR.DDRCPLPEN
  [1] TIM{i}EN — TIM{i} clock enable
    values as RCC_DDRCPCFGR.DDRCPEN
  [0] TIM{i}RST — TIM{i} reset
    0=Writing 0 releases TIM{i} reset; 1=Writing 1 asserts TIM{i} reset
{0x6F8+4i} RCC_TIM{i}CFGR reset 0x4 (i=10..17) — RCC TIM{i} configuration register
  fields as RCC_TIM1CFGR
0x740 RCC_TIM20CFGR reset 0x4 — RCC TIM20 configuration register
  [2] TIM20LPEN — TIM20 clock enable during CSleep
    values as RCC_DDRCPCFGR.DDRCPLPEN
  [1] TIM20EN — TIM20 clock enable
    values as RCC_DDRCPCFGR.DDRCPEN
  [0] TIM20RST — TIM20 reset
    0=Writing 0 releases TIM20 reset; 1=Writing 1 asserts TIM20 reset
0x744 RCC_LPTIM1CFGR reset 0x4 — RCC LPTIM1 configuration register
  [2] LPTIM1LPEN — LPTIM1 clock enable during CSleep
    values as RCC_DDRCPCFGR.DDRCPLPEN
  [1] LPTIM1EN — LPTIM1 clock enable
    values as RCC_DDRCPCFGR.DDRCPEN
  [0] LPTIM1RST — LPTIM1 reset
    0=Writing 0 releases LPTIM1 reset; 1=Writing 1 asserts LPTIM1 reset
0x748 RCC_LPTIM2CFGR reset 0x4 — RCC LPTIM2 configuration register
  [2] LPTIM2LPEN — LPTIM2 clock enable during CSleep
    values as RCC_DDRCPCFGR.DDRCPLPEN
  [1] LPTIM2EN — LPTIM2 clock enable
    values as RCC_DDRCPCFGR.DDRCPEN
  [0] LPTIM2RST — LPTIM2 reset
    0=Writing 0 releases LPTIM2 reset; 1=Writing 1 asserts LPTIM2 reset
{0x740+4i} RCC_LPTIM{i}CFGR reset 0x4 (i=3..5) — RCC LPTIM{i} configuration register
  [3] LPTIM{i}AMEN — LPTIM{i} autonomous clock mode enable
    values as RCC_LPSRAM1CFGR.LPSRAM1AMEN
  [2] LPTIM{i}LPEN — LPTIM{i} clock enable during CSleep
    values as RCC_DDRCPCFGR.DDRCPLPEN
  [1] LPTIM{i}EN — LPTIM{i} clock enable
    values as RCC_DDRCPCFGR.DDRCPEN
  [0] LPTIM{i}RST — LPTIM{i} reset
    0=Writing 0 releases LPTIM{i} reset; 1=Writing 1 asserts LPTIM{i} reset
{0x754+4i} RCC_SPI{i}CFGR reset 0x4 (i=1..7) — RCC SPI{i} configuration register
  [2] SPI{i}LPEN — SPI{i} clock enable during CSleep
    values as RCC_DDRCPCFGR.DDRCPLPEN
  [1] SPI{i}EN — SPI{i} clock enable
    values as RCC_DDRCPCFGR.DDRCPEN
  [0] SPI{i}RST — SPI{i} reset
    0=Writing 0 releases SPI{i} reset; 1=Writing 1 asserts SPI{i} reset
0x774 RCC_SPI8CFGR reset 0x4 — RCC SPI8 configuration register
  [3] SPI8AMEN — SPI8 autonomous clock mode enable
    values as RCC_LPSRAM1CFGR.LPSRAM1AMEN
  [2] SPI8LPEN — SPI8 clock enable during CSleep
    values as RCC_DDRCPCFGR.DDRCPLPEN
  [1] SPI8EN — SPI8 clock enable
    values as RCC_DDRCPCFGR.DDRCPEN
  [0] SPI8RST — SPI8 reset
    0=Writing 0 releases SPI8 reset; 1=Writing 1 asserts SPI8 reset
0x778 RCC_SPDIFRXCFGR reset 0x4 — RCC SPDIFRX configuration register
  [2] SPDIFRXLPEN — SPDIFRX clock enable during CSleep
    values as RCC_DDRCPCFGR.DDRCPLPEN
  [1] SPDIFRXEN — SPDIFRX clock enable
    values as RCC_DDRCPCFGR.DDRCPEN
  [0] SPDIFRXRST — SPDIFRX reset
    0=Writing 0 releases SPDIFRX reset; 1=Writing 1 asserts SPDIFRX reset
{0x778+4i} RCC_USART{i}CFGR reset 0x4 (i=1..3) — RCC USART{i} configuration register
  [2] USART{i}LPEN — USART{i} clock enable during CSleep
    values as RCC_DDRCPCFGR.DDRCPLPEN
  [1] USART{i}EN — USART{i} clock enable
    values as RCC_DDRCPCFGR.DDRCPEN
  [0] USART{i}RST — USART{i} reset
    0=Writing 0 releases USART{i} reset; 1=Writing 1 asserts USART{i} reset
0x788 RCC_UART4CFGR reset 0x4 — RCC UART4 configuration register
  [2] UART4LPEN — UART4 clock enable during CSleep
    values as RCC_DDRCPCFGR.DDRCPLPEN
  [1] UART4EN — UART4 clock enable
    values as RCC_DDRCPCFGR.DDRCPEN
  [0] UART4RST — UART4 reset
    0=Writing 0 releases UART4 reset; 1=Writing 1 asserts UART4 reset
0x78C RCC_UART5CFGR reset 0x4 — RCC UART5 configuration register
  [2] UART5LPEN — UART5 clock enable during CSleep
    values as RCC_DDRCPCFGR.DDRCPLPEN
  [1] UART5EN — UART5 clock enable
    values as RCC_DDRCPCFGR.DDRCPEN
  [0] UART5RST — UART5 reset
    0=Writing 0 releases UART5 reset; 1=Writing 1 asserts UART5 reset
0x790 RCC_USART6CFGR reset 0x4 — RCC USART6 configuration register
  [2] USART6LPEN — USART6 clock enable during CSleep
    values as RCC_DDRCPCFGR.DDRCPLPEN
  [1] USART6EN — USART6 clock enable
    values as RCC_DDRCPCFGR.DDRCPEN
  [0] USART6RST — USART6 reset
    0=Writing 0 releases USART6 reset; 1=Writing 1 asserts USART6 reset
{0x778+4i} RCC_UART{i}CFGR reset 0x4 (i=7..9) — RCC UART{i} configuration register
  [2] UART{i}LPEN — UART{i} clock enable during CSleep
    values as RCC_DDRCPCFGR.DDRCPLPEN
  [1] UART{i}EN — UART{i} clock enable
    values as RCC_DDRCPCFGR.DDRCPEN
  [0] UART{i}RST — UART{i} reset
    0=Writing 0 releases UART{i} reset; 1=Writing 1 asserts UART{i} reset
0x7A0 RCC_LPUART1CFGR reset 0x4 — RCC LPUART1 configuration register
  [3] LPUART1AMEN — LPUART1 autonomous clock mode enable
    values as RCC_LPSRAM1CFGR.LPSRAM1AMEN
  [2] LPUART1LPEN — LPUART1 clock enable during CSleep
    values as RCC_DDRCPCFGR.DDRCPLPEN
  [1] LPUART1EN — LPUART1 clock enable
    values as RCC_DDRCPCFGR.DDRCPEN
  [0] LPUART1RST — LPUART1 reset
    0=Writing 0 releases LPUART1 reset; 1=Writing 1 asserts LPUART1 reset
{0x7A0+4i} RCC_I2C{i}CFGR reset 0x4 (i=1..7) — RCC I2C{i} configuration register
  [2] I2C{i}LPEN — I2C{i} clock enable during CSleep
    values as RCC_DDRCPCFGR.DDRCPLPEN
  [1] I2C{i}EN — I2C{i} clock enable
    values as RCC_DDRCPCFGR.DDRCPEN
  [0] I2C{i}RST — I2C{i} reset
    0=Writing 0 releases I2C{i} reset; 1=Writing 1 asserts I2C{i} reset
0x7C0 RCC_I2C8CFGR reset 0x4 — RCC I2C8 configuration register
  [3] I2C8AMEN — I2C8 autonomous clock mode enable
    values as RCC_LPSRAM1CFGR.LPSRAM1AMEN
  [2] I2C8LPEN — I2C8 peripheral clocks enable during CSleep mode
    values as RCC_DDRCPCFGR.DDRCPLPEN
  [1] I2C8EN — I2C8 peripheral clocks enable
    values as RCC_DDRCPCFGR.DDRCPEN
  [0] I2C8RST — I2C8 reset
    0=Writing 0 releases I2C8 reset; 1=Writing 1 asserts I2C8 reset
{0x7C0+4i} RCC_SAI{i}CFGR reset 0x4 (i=1..4) — RCC SAI{i} configuration register
  [2] SAI{i}LPEN — SAI{i} clock enable during CSleep
    values as RCC_DDRCPCFGR.DDRCPLPEN
  [1] SAI{i}EN — SAI{i} clock enable
    values as RCC_DDRCPCFGR.DDRCPEN
  [0] SAI{i}RST — SAI{i} reset
    0=Writing 0 releases SAI{i} reset; 1=Writing 1 asserts SAI{i} reset
